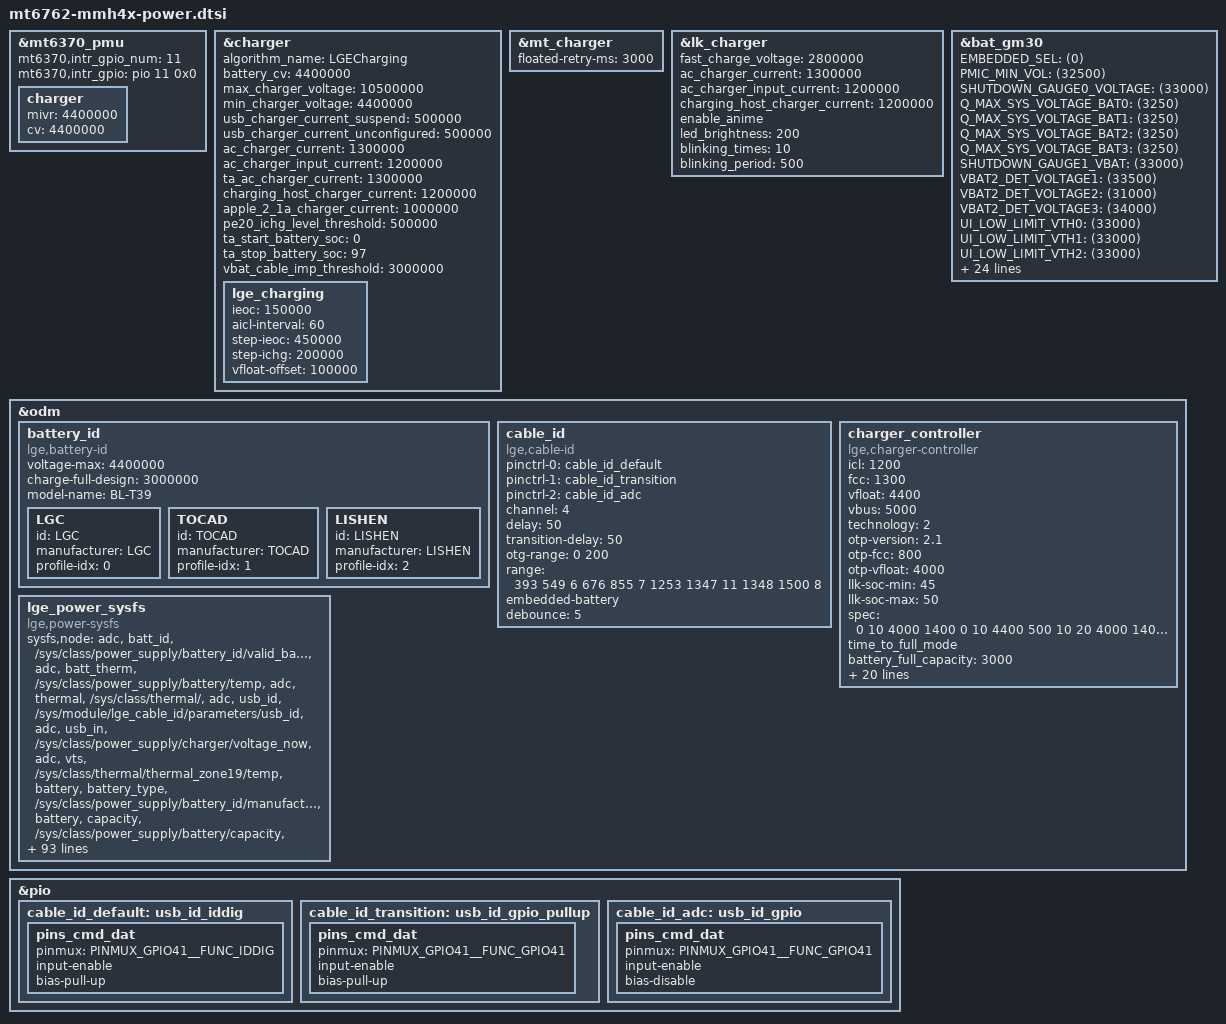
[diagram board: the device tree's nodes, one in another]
/*
 * LG Electronics MT6765 HDK power device tree source
 *
 * Copyright (c) 2018 LG Electronics Co., Ltd.
 *              http://www.lge.com
 *
 */

&mt6370_pmu {
	mt6370,intr_gpio_num = <11>; /* direct defined GPIO num */
	mt6370,intr_gpio = <&pio 11 0x0>;

	charger {
		interrupt-names = "chg_mivr", "chg_aiclmeasi",
			"attachi","ovpctrl_uvp_d_evt", "chg_wdtmri",
			"chg_vbusov","chg_tmri", "chg_treg", "pwr_rdy";
		mivr = <4400000>;	/* uV */
		cv = <4400000>;		/* uA */
	};
};

&charger {
	algorithm_name = "LGECharging";

	/* common */
	battery_cv = <4400000>;
	max_charger_voltage = <10500000>;
	min_charger_voltage = <4400000>;

	/* usb charging curent */
	usb_charger_current_suspend = <500000>;
	usb_charger_current_unconfigured = <500000>;

	/* charging current */
	ac_charger_current = <1300000>;
	ac_charger_input_current = <1200000>;
	ta_ac_charger_current = <1300000>;
	charging_host_charger_current = <1200000>;
	apple_2_1a_charger_current = <1000000>;

	/* PE 2.0 */
	pe20_ichg_level_threshold = <500000>; /* uA */
	ta_start_battery_soc = <0>;
	ta_stop_battery_soc = <97>;

	/* cable measurement impedance */
	vbat_cable_imp_threshold = <3000000>; /* uV */

	/* LGE Charging Algorithm */
	lge_charging {
		ieoc = <150000>;
		aicl-interval = <60>;

		step-ieoc = <450000>;
		step-ichg = <200000>;
		vfloat-offset = <100000>;
	};
};

&mt_charger {
	floated-retry-ms = <3000>; /* 3000 ms */
};

&lk_charger {
	fast_charge_voltage = <2800000>;
	ac_charger_current = <1300000>;
	ac_charger_input_current = <1200000>;
	charging_host_charger_current = <1200000>;

	enable_anime;
	led_brightness = <200>;
	blinking_times = <10>;
	blinking_period = <500>;
};

&bat_gm30 {
	/*	Configures whether using embedded battery or not.*/
	EMBEDDED_SEL = <(0)>;

	/*
	 * Below setting is cut off 3.3 parameter.
	 * If use cutoff 3.4V, use MTK original parameter
	 */
	/*	vboot voltage for gauge 0%.*/
	PMIC_MIN_VOL = <(32500)>;
	/*	shutdown gauge 0% voltage*/
	SHUTDOWN_GAUGE0_VOLTAGE = <(33000)>;
	/*	System shut down voltage.*/
	Q_MAX_SYS_VOLTAGE_BAT0 = <(3250)>;
	/*	System shut down voltage.*/
	Q_MAX_SYS_VOLTAGE_BAT1 = <(3250)>;
	/*	System shut down voltage.*/
	Q_MAX_SYS_VOLTAGE_BAT2 = <(3250)>;
	/*	System shut down voltage.*/
	Q_MAX_SYS_VOLTAGE_BAT3 = <(3250)>;
	/* no used. Ignore. Just for align with shutdown condition 3.3v */
	SHUTDOWN_GAUGE1_VBAT = <(33000)>;
	/* Related to low voltage tracking */
	VBAT2_DET_VOLTAGE1 = <(33500)>;
	VBAT2_DET_VOLTAGE2 = <(31000)>;
	VBAT2_DET_VOLTAGE3 = <(34000)>;
	/* cut off scenario. below setting means that 2% shutdown with 3.3v. */
	UI_LOW_LIMIT_VTH0 = <(33000)>;
	UI_LOW_LIMIT_VTH1 = <(33000)>;
	UI_LOW_LIMIT_VTH2 = <(33000)>;
	UI_LOW_LIMIT_VTH3 = <(33000)>;
	UI_LOW_LIMIT_VTH4 = <(33000)>;

	g_Q_MAX_SYS_VOLTAGE = <3250 3250 3250 3250>;
	g_PMIC_MIN_VOL = <32500 32500 32500 32500
			32500 32500 32500 32500
			32500 32500 32500 32500
			31200 31200 31200 31200
			30000 30000 30000 30000
			30000 30000 30000 30000
			30000 30000 30000 30000
			30000 30000 30000 30000
			30000 30000 30000 30000
			30000 30000 30000 30000>;

	g_QMAX_SYS_VOL = <32500 32500 32500 32500
			32500 32500 32500 32500
			32500 32500 32500 32500
			31900 31900 31900 31900
			31800 31800 31800 31800
			32500 32500 32500 32500
			32500 32500 32500 32500
			32500 32500 32500 32500
			32500 32500 32500 32500
			32500 32500 32500 32500>;
	/*
	 * Above setting value is cut off 3.3 parameter.
	 * If use cutoff 3.4V, use MTK original parameter
	 */

	/*      Pseudo 100% percentage at T0.*/
	g_FG_PSEUDO100_T0 = <(95)>;
	/*      Pseudo 100% percentage at T1.*/
	g_FG_PSEUDO100_T1 = <(95)>;
	/*      Pseudo 100% percentage at T2.*/
	g_FG_PSEUDO100_T2 = <(95)>;
	/*      Pseudo 100% percentage at T3.*/
	g_FG_PSEUDO100_T3 = <(95)>;

	PSEUDO1_SEL = <(0)>;

	g_FG_PSEUDO1 = <1  1  1  1
			1  1  1  1
			1  1  1  1
			1  1  1  1
			1  1  1  1
			1  1  1  1
			1  1  1  1
			1  1  1  1
			1  1  1  1
			1  1  1  1>;

	DIFFERENCE_VOLTAGE_UPDATE = <(-1)>;
	AGING1_UPDATE_SOC = <(10)>;
	AGING1_LOAD_SOC = <(50)>;
	ZCV_SUSPEND_TIME = <(9)>;
	SLEEP_CURRENT_AVG = <(500)>; /*0.1mA*/

	HWOCV_OLDOCV_DIFF_CHR = <(1500)>;
	SWOCV_OLDOCV_DIFF_CHR = <(1500)>;

	POWER_ON_CAR_CHR = <(20)>;
	POWER_ON_CAR_NOCHR = <(-35)>;

	/*The ui_soc will keep 100% until SOC drop X percents after unplugged.*/
	KEEP_100_PERCENT = <(2)>;

#include "../battery_BL-T39.dtsi"
};

&odm {
	/* Battery ID */
	battery_id {
		compatible = "lge,battery-id";
		voltage-max = <4400000>;
		charge-full-design = <3000000>;
		model-name = "BL-T39";

		LGC {
			id = "LGC";
			manufacturer = "LGC";
			profile-idx = <0>;
		};
		TOCAD {
			id = "TOCAD";
			manufacturer = "TOCAD";
			profile-idx = <1>;
		};
		LISHEN {
			id = "LISHEN";
			manufacturer = "LISHEN";
			profile-idx = <2>;
		};
	};

	/* Cable ID */
	cable_id {
		compatible = "lge,cable-id";

		pinctrl-names = "default", "transition", "adc";
		pinctrl-0 = <&cable_id_default>;
		pinctrl-1 = <&cable_id_transition>;
		pinctrl-2 = <&cable_id_adc>;

		channel = <4>;
		delay = <50>;
		transition-delay = <50>;

		/*
		 * Pull-up : 1.8V 150k (1%)
		 * Pull-down : 680k (1%)
		 * ID : 56k (20%), 130k (20%), 910k (20%)
		 * ADC Accuracy : +-10mV
		 */
		otg-range = <0	200>;
		range = <
		/*	min 	max 	type	*/
			393	549	6	/* 6: LT_CABLE_56K */
			676	855	7	/* 7: LT_CABLE_130K */
			1253	1347	11	/* 11: LT_CABLE_910K */
			1348	1500	8	/* 8: USB_CABLE_400MA */
		>;

		embedded-battery;
		debounce = <5>;
	};

	/* Charger Controller */
	charger_controller {
		compatible = "lge,charger-controller";

		/* base information */
		icl = <1200>;
		fcc = <1300>;
		vfloat = <4400>;
		vbus = <5000>;
		technology = <2>;

		/* otp */
		otp-version = "2.1";
		otp-fcc = <800>;
		otp-vfloat = <4000>;

		/* llk */
		llk-soc-min = <45>;
		llk-soc-max = <50>;

		/* spec */
		spec = <
			 0 10 4000 1400	/* 0.5C */
			 0 10 4400 500	/* 0.2C */
			10 20 4000 1400 /* 0.5C */
			10 20 4400 500  /* 0.2C */
			20 45 4100 2800	/* 1.0C */
			20 45 4400 2000	/* 0.7C */
			45 60 4100 1400	/* 0.5C */
		>;

		/* time to full */
		time_to_full_mode;
		battery_full_capacity = <3000>;
		sdp_current = <500>;
		dcp_current = <1200>;
		pep_current = <2200>;
		non_std_current = <500>;
		report_ttf_comp = <0>;
		sdp_comp = <(-2)>;
		dcp_comp = <6>;
		cdp_comp = <0>;
		non_std_comp = <(-2)>;
		min_comp = <0>;
			/*lgc tocad atl byd lishen*/
		batt_comp = <(-5) 0 0 0 (-7)>;
			/* current soc */
		cc_data = <1200 0>;
			/* current soc time */
		cv_data = <1031 911 1136
			997 916 1091
			963 921 1045
			953 926 997
			935 931 948
			900 936 896
			860 941 842
			826 946 785
			785 951 728
			743 956 667
			718 961 603
			677 966 537
			642 971 466
			609 976 390
			561 981 313
			534 987 227
			508 989 178
			491 991 128
			468 993 73
			468 995 15
			456 996 0
			430 1000 0>;

		/* game */
		game-icl = <900>;

		game-light-icl = <900>;
		game-light-load = <80>;
		game-light-sec = <100>;

		game-lowbatt-icl = <900>;
		game-lowbatt-soc = <15>;
	};

	/* Unified Power Sysfs */
	lge_power_sysfs {
		compatible = "lge,power-sysfs";
		sysfs,node =
			/* adc group */
			"adc", "batt_id", "/sys/class/power_supply/battery_id/valid_batt_id",
			"adc", "batt_therm", "/sys/class/power_supply/battery/temp",
			"adc", "thermal", "/sys/class/thermal/",
			"adc", "usb_id", "/sys/module/lge_cable_id/parameters/usb_id",
			"adc", "usb_in", "/sys/class/power_supply/charger/voltage_now",
			"adc", "vts", "/sys/class/thermal/thermal_zone19/temp",
			/* battery group */
			"battery", "battery_type", "/sys/class/power_supply/battery_id/manufacturer",
			"battery", "capacity", "/sys/class/power_supply/battery/capacity",
			"battery", "cycle", "/sys/class/power_supply/battery/battery_cycle",
			"battery", "raw_capacity", "/sys/class/power_supply/battery/raw_capacity",
			"battery", "health", "/sys/class/power_supply/battery/health",
			"battery", "present", "/sys/class/power_supply/battery/present",
			"battery", "pseudo_batt", "/sys/module/pseudo_power_supply/parameters/pseudo_batt",
			"battery", "temp", "/sys/class/power_supply/battery/temp",
			"battery", "valid_batt_id", "/sys/class/power_supply/battery_id/valid_batt_id",
			"battery", "check_batt_id_for_aat", "/sys/class/power_supply/battery_id/check_batt_id_for_aat",
			"battery", "voltage_now", "/sys/class/power_supply/battery/voltage_now",
			"battery", "status", "/sys/class/power_supply/battery/status",
			"battery", "time_to_full_now", "/sys/class/power_supply/charger_controller/time_to_full_now",
			"battery", "charge_full", "/sys/class/power_supply/battery/charge_full",
			"battery", "charge_full_design", "/sys/class/power_supply/battery/charge_full_design",
			"battery", "charge_counter", "/sys/class/power_supply/battery/charge_counter",
			"battery", "battery_age", "/sys/class/power_supply/battery/battery_age",
			"battery", "battery_age_level", "/sys/class/power_supply/battery/battery_age_level",
			"battery", "condition", "/sys/class/power_supply/battery/battery_condition",
			/* charger group */
			"charger", "ac_online", "/sys/class/power_supply/ac/online",
			"charger", "usb_online", "/sys/class/power_supply/usb/online",
			"charger", "present", "/sys/class/power_supply/charger/online",
			"charger", "ibat_current", "/sys/class/power_supply/battery/current_now",
			"charger", "ichg_current", "/sys/class/power_supply/usb/current_max",
			"charger", "charging_enabled", "/sys/class/power_supply/charger_controller/charging_enabled",
			"charger", "restricted_charging", "/sys/module/charger_controller/parameters/restricted_charging",
			"charger", "store_demo_enabled", "/sys/class/power_supply/charger_controller/store_demo_enabled",
			"charger", "fastchg", "/sys/class/power_supply/charger/fastchg",
			"charger", "fastchg_support", "/sys/class/power_supply/charger/fastchg_support",
			"charger", "incompatible", "/sys/class/power_supply/charger/incompatible_chg",
			"charger", "pseudo_hvdcp", "/sys/module/pseudo_power_supply/parameters/hvdcp_mode",
			"charger", "chgstep", "/sys/module/charger_controller/parameters/chgstep",
			/* lcd group */
			"lcd", "brightness", "/sys/class/leds/lcd-backlight/brightness",
			"lcd", "max_brightness", "/sys/class/leds/lcd-backlight/max_brightness",
			/* key led group */
			"key_led", "red_brightness", "/sys/class/leds/red/brightness",
			"key_led", "setting", "/sys/class/leds/red/pattern_id",
			/* cpu group */
			"cpu", "game_mode", "/proc/ppm/policy/auto_game_limit",
			/* gpu group */
			/* platform group */
			/* perf service feature group */
			/* testmode group */
			"testmode", "batt_id", "/sys/class/power_supply/battery_id/batt_id",
			"testmode", "battexist", "/sys/class/power_supply/battery/present",
			"testmode", "charge", "/sys/module/charger_controller/parameters/atcmd_charge",
			"testmode", "chcomp", "/sys/module/charger_controller/parameters/atcmd_chcomp",
			"testmode", "chgmodeoff", "/sys/module/charger_controller/parameters/atcmd_chgmodeoff",
			"testmode", "current_max", "/sys/class/power_supply/usb/current_max",
			"testmode", "current_now", "/sys/class/power_supply/battery/current_now",
			"testmode", "fuelval", "/sys/class/power_supply/battery/capacity",
			"testmode", "temp", "/sys/module/charger_controller/parameters/atcmd_batmp",
			"testmode", "usb_id", "/sys/module/lge_cable_id/parameters/atcmd_usb_id",
			"testmode", "valid_batt_id", "/sys/class/power_supply/battery_id/check_batt_id_for_aat",
			"testmode", "voltage_now", "/sys/class/power_supply/battery/voltage_now";
	};
};

&pio {
	cable_id_default: usb_id_iddig {
		pins_cmd_dat {
			pinmux = <PINMUX_GPIO41__FUNC_IDDIG>;
			input-enable;
			bias-pull-up;
		};
	};
	cable_id_transition: usb_id_gpio_pullup {
		pins_cmd_dat {
			pinmux = <PINMUX_GPIO41__FUNC_GPIO41>;
			input-enable;
			bias-pull-up;
		};
	};
	cable_id_adc: usb_id_gpio {
		pins_cmd_dat {
			pinmux = <PINMUX_GPIO41__FUNC_GPIO41>;
			input-enable;
			bias-disable;
		};
	};
};
